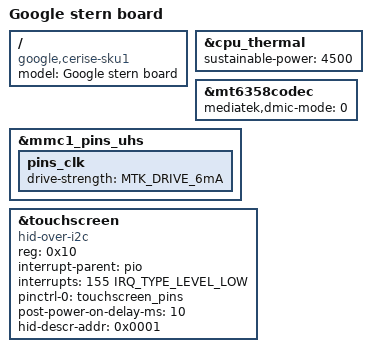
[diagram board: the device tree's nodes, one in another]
// SPDX-License-Identifier: (GPL-2.0 OR MIT)
/*
 * Copyright 2020 Google LLC
 */

/dts-v1/;
#include "mt8183-kukui-jacuzzi.dtsi"
#include "mt8183-kukui-audio-da7219-rt1015p.dtsi"

/ {
	model = "Google stern board";
	compatible = "google,cerise-sku1", "google,cerise", "mediatek,mt8183";
};

&cpu_thermal {
	sustainable-power = <4500>; /* milliwatts */
};

&mt6358codec {
	mediatek,dmic-mode = <0>; /* two-wire */
};

&mmc1_pins_uhs {
	pins_clk {
		drive-strength = <MTK_DRIVE_6mA>;
	};
};

&touchscreen {
	status = "okay";

	compatible = "hid-over-i2c";
	reg = <0x10>;
	interrupt-parent = <&pio>;
	interrupts = <155 IRQ_TYPE_LEVEL_LOW>;
	pinctrl-names = "default";
	pinctrl-0 = <&touchscreen_pins>;

	post-power-on-delay-ms = <10>;
	hid-descr-addr = <0x0001>;
};
